AUTOSAR XML (schema 4-3-0)
package /Battery_CAN_Bus/ECUs
  ecu instance Info_Node: diagnostic-address=76773662, sleep-mode-supported=true, wake-up-over-bus-supported=true
    can communication controller Info_Node_Batt_CANController
    can communication controller Info_Node_Veh_CANController
    can communication controller Info_Node_Debug_CANController
    can communication connector Info_Node_Batt_CANConnector: comm-controller=Info_Node_Batt_CANController
    can communication connector Info_Node_Veh_CANConnector: comm-controller=Info_Node_Veh_CANController
    can communication connector Info_Node_Debug_CANConnector: comm-controller=Info_Node_Debug_CANController
  ecu instance VIC: diagnostic-address=1270719688, sleep-mode-supported=true, wake-up-over-bus-supported=true
    4 x can communication controller:
      VIC_Veh_CANController
      VIC_Batt_CANController
      VIC_Veh_J1939_CANController  # Virtual controller to handle the switch between CAN2B and J1939 in the CAN0 hw controller
      VIC_Debug_CANController
    can communication connector VIC_Veh_CANConnector: comm-controller=VIC_Veh_CANController
    can communication connector VIC_Batt_CANConnector: comm-controller=VIC_Batt_CANController
    can communication connector VIC_Veh_J1939Connector: comm-controller=VIC_Veh_J1939_CANController, pnc-wakeup-can-id-extended=true
    can communication connector VIC_Debug_CANConnector: comm-controller=VIC_Debug_CANController
package /E2E_Datatransformation
  data transformation set DATATRANSF_SET_EB
    data transformation BaseTrans_Profile_1C: execute-despite-data-unavailability=true, transformer-chain=[ComBasedTransformer, E2E_Profile_1C]  # Base Transformer Base Profile 1C
    transformation technology E2E_Profile_1C:  # E2E Profile 1C
      buffer-properties={header-length=0, in-place=false}
      needs-original-data=false
      protocol=E2E
      end-to-end-transformation-description{counter-offset=8, crc-offset=0, data-id-mode=LOWER-12-BIT, data-id-nibble-offset=12, max-delta-counter=3, max-error-state-init=1, max-error-state-invalid=1, max-error-state-valid=1, max-no-new-or-repeated-data=3, min-ok-state-init=1, min-ok-state-invalid=1, min-ok-state-valid=1, offset=0, profile-behavior=R-4--2, profile-name=PROFILE_01, sync-counter-init=1, upper-header-bits-to-shift=0, window-size=3}
      transformer-class=SAFETY
      version=1.0.0
    transformation technology ComBasedTransformer: buffer-properties={buffer-computation=compu-rational-coeffs={compu-numerator=[0, 1], compu-denominator=1}, header-length=0, in-place=false}, protocol=COMBased, transformer-class=SERIALIZER, version=1
package /Vehicle_CAN_Bus/Clusters
  can cluster Vehicle_CAN_Bus: baudrate=500000
    can physical channel Vehicle_CANChannel
      comm-connectors:
        Thermal_Management_System_ECU_CANConnector
        Vehicle_Control_Unit_CANConnector
        VIC_Veh_CANConnector
        Info_Node_Veh_CANConnector
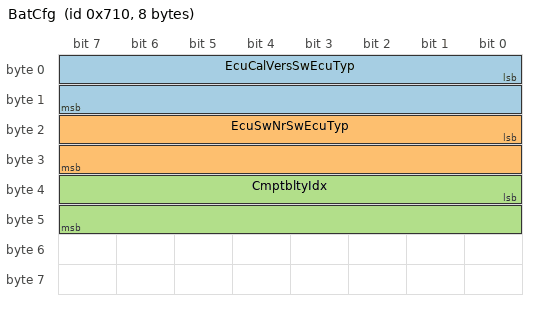
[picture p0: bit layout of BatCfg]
      frame BatCfg: id 0x710, from VIC, to Vehicle_Control_Unit, frame-length=8, can-addressing-mode=EXTENDED, can-frame-rx-behavior=CAN-20, can-frame-tx-behavior=CAN-20  # Configuration of the ECU
        pdu BatCfg: length=8, transmission-mode-true-timing=cyclic-timing=time-period=5, unused-bit-pattern=255
          signal EcuCalVersSwEcuTyp: start 0, 16 bit, little-endian, data-type-policy=OVERRIDE, base-type=EcuCalVersSwEcuTyp_Coding, compu {0=Info not available (default), 1=BMS, 2=VIC}, range phys 0..65535, to Vehicle_Control_Unit  # Calibration data ECU type
          signal EcuSwNrSwEcuTyp: start 16, 16 bit, little-endian, data-type-policy=OVERRIDE, base-type=EcuSwNrSwEcuTyp_Coding, compu {0=Info not available (default), 1=BMS, 2=VIC}, range phys 0..65535, to Vehicle_Control_Unit  # Software ECU type
          signal CmptbltyIdx: start 32, 16 bit, little-endian, data-type-policy=OVERRIDE, base-type=CmptbltyIdx_Coding, compu {identical}, range phys 0..65535, to Vehicle_Control_Unit  # Compatibility index of the CAN communication between BMS and VIC
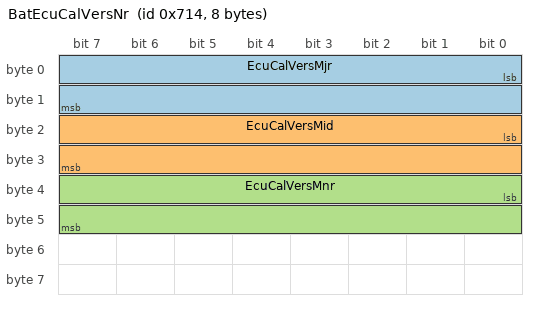
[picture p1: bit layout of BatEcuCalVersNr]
      frame BatEcuCalVersNr: id 0x714, from VIC, to Vehicle_Control_Unit, frame-length=8, can-addressing-mode=EXTENDED, can-frame-rx-behavior=CAN-20, can-frame-tx-behavior=CAN-20  # ECU calibration release numbers (unique identification in combination with BatEcuSwNr)
        pdu BatEcuCalVersNr: length=8, transmission-mode-condition{data-filter=data-filter-type=ALWAYS, i-signal-in-i-pdu=BatEcuCalVersNr_EcuCalVersMnr}, transmission-mode-true-timing=cyclic-timing=time-period=5, unused-bit-pattern=255
          signal EcuCalVersMjr: start 0, 16 bit, little-endian, data-type-policy=OVERRIDE, base-type=EcuCalVersMjr_Coding, compu {identical}, range phys 0..65535, to Vehicle_Control_Unit  # Calibration data major release number
          signal EcuCalVersMid: start 16, 16 bit, little-endian, data-type-policy=OVERRIDE, base-type=EcuCalVersMid_Coding, compu {identical}, range phys 0..65535, to Vehicle_Control_Unit  # Calibration data feature release number
          signal EcuCalVersMnr: start 32, 16 bit, little-endian, data-type-policy=OVERRIDE, base-type=EcuCalVersMnr_Coding, compu {identical}, range phys 0..65535, to Vehicle_Control_Unit  # Calibration data bugfix release number
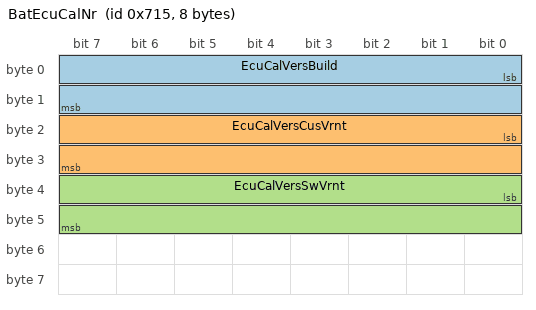
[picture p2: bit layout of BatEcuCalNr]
      frame BatEcuCalNr: id 0x715, from VIC, to Vehicle_Control_Unit, frame-length=8, can-addressing-mode=EXTENDED, can-frame-rx-behavior=CAN-20, can-frame-tx-behavior=CAN-20  # ECU calibration build and variant numbers (unique identification in combination with BatEcuCalVersNr)
        pdu BatEcuCalNr: length=8, transmission-mode-condition{data-filter=data-filter-type=ALWAYS, i-signal-in-i-pdu=BatEcuCalNr_EcuCalVersSwVrnt}, transmission-mode-true-timing=cyclic-timing=time-period=5, unused-bit-pattern=255
          signal EcuCalVersBuild: start 0, 16 bit, little-endian, data-type-policy=OVERRIDE, base-type=EcuCalVersBuild_Coding, compu {identical}, range phys 0..65535, to Vehicle_Control_Unit  # Calibration data build version number
          signal EcuCalVersCusVrnt: start 16, 16 bit, little-endian, data-type-policy=OVERRIDE, base-type=EcuCalVersCusVrnt_Coding, compu {identical}, range phys 0..65535, to Vehicle_Control_Unit  # Calibration data customer variant
          signal EcuCalVersSwVrnt: start 32, 16 bit, little-endian, data-type-policy=OVERRIDE, base-type=EcuCalVersSwVrnt_Coding, compu {identical}, range phys 0..65535, to Vehicle_Control_Unit  # Calibration data software variant
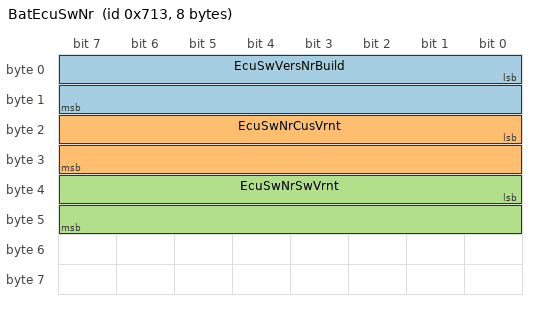
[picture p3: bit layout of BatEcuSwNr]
      frame BatEcuSwNr: id 0x713, from VIC, to Vehicle_Control_Unit, frame-length=8, can-addressing-mode=EXTENDED, can-frame-rx-behavior=CAN-20, can-frame-tx-behavior=CAN-20  # ECU software build and variant numbers (unique identification in combination with BatEcuSwVersNr)
        pdu BatEcuSwNr: length=8, transmission-mode-condition{data-filter=data-filter-type=ALWAYS, i-signal-in-i-pdu=BatEcuSwNr_EcuSwNrSwVrnt}, transmission-mode-true-timing=cyclic-timing=time-period=5, unused-bit-pattern=255
          signal EcuSwVersNrBuild: start 0, 16 bit, little-endian, data-type-policy=OVERRIDE, base-type=EcuSwVersNrBuild_Coding, compu {identical}, range phys 0..65535, to Vehicle_Control_Unit  # Software build version number
          signal EcuSwNrCusVrnt: start 16, 16 bit, little-endian, data-type-policy=OVERRIDE, base-type=EcuSwNrCusVrnt_Coding, compu {identical}, range phys 0..65535, to Vehicle_Control_Unit  # Software customer variant
          signal EcuSwNrSwVrnt: start 32, 16 bit, little-endian, data-type-policy=OVERRIDE, base-type=EcuSwNrSwVrnt_Coding, compu {identical}, range phys 0..65535, to Vehicle_Control_Unit  # Software variant
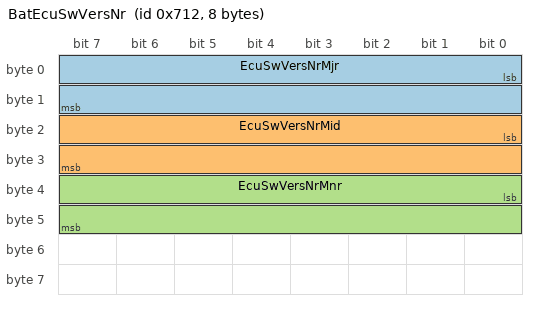
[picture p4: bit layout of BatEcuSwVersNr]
      frame BatEcuSwVersNr: id 0x712, from VIC, to Vehicle_Control_Unit, frame-length=8, can-addressing-mode=EXTENDED, can-frame-rx-behavior=CAN-20, can-frame-tx-behavior=CAN-20  # ECU software release numbers (unique identification in combination with BatEcuSwNr)
        pdu BatEcuSwVersNr: length=8, transmission-mode-condition{data-filter=data-filter-type=ALWAYS, i-signal-in-i-pdu=BatEcuSwVersNr_EcuSwVersNrMnr}, transmission-mode-true-timing=cyclic-timing=time-period=5, unused-bit-pattern=255
          signal EcuSwVersNrMjr: start 0, 16 bit, little-endian, data-type-policy=OVERRIDE, base-type=EcuSwVersNrMjr_Coding, compu {identical}, range phys 0..65535, to Vehicle_Control_Unit  # Software major release number
          signal EcuSwVersNrMid: start 16, 16 bit, little-endian, data-type-policy=OVERRIDE, base-type=EcuSwVersNrMid_Coding, compu {identical}, range phys 0..65535, to Vehicle_Control_Unit  # Software feature release number
          signal EcuSwVersNrMnr: start 32, 16 bit, little-endian, data-type-policy=OVERRIDE, base-type=EcuSwVersNrMnr_Coding, compu {identical}, range phys 0..65535, to Vehicle_Control_Unit  # Software bugfix release number
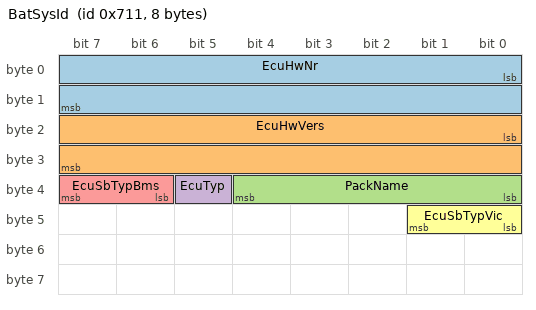
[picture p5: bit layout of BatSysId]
      frame BatSysId: id 0x711, from VIC, to Vehicle_Control_Unit, frame-length=8, can-addressing-mode=EXTENDED, can-frame-rx-behavior=CAN-20, can-frame-tx-behavior=CAN-20  # ECU hardware identification
        pdu BatSysId: length=8, transmission-mode-condition{data-filter=data-filter-type=ALWAYS, i-signal-in-i-pdu=BatSysId_EcuHwVers}, transmission-mode-true-timing=cyclic-timing=time-period=5, unused-bit-pattern=255
          signal EcuHwNr: start 0, 16 bit, little-endian, data-type-policy=OVERRIDE, base-type=EcuHwNr_Coding, compu {identical}, range phys 0..65535, to Vehicle_Control_Unit  # ECU hardware number
          signal EcuHwVers: start 16, 16 bit, little-endian, data-type-policy=OVERRIDE, base-type=EcuHwVers_Coding, compu {identical}, range phys 0..65535, to Vehicle_Control_Unit  # ECU hardware version
          signal PackName: start 32, 5 bit, little-endian, data-type-policy=OVERRIDE, base-type=PackName_Coding, compu {0=Pack1_1 or Standalone, 1..6=Pack1_2..Pack1_7, 7..12=Pack2_1..Pack2_6, 30=VIC, 31=Info not available}, range phys 0..31, to Vehicle_Control_Unit  # Name of the battery component
          signal EcuTyp: start 37, 1 bit, little-endian, data-type-policy=OVERRIDE, base-type=EcuTyp_Coding, compu {0=BMS, 1=VIC}, range phys 0..1, to Vehicle_Control_Unit  # Type of ECU
          signal EcuSbTypBms: start 38, 2 bit, little-endian, data-type-policy=OVERRIDE, base-type=EcuSbTypBms_Coding, compu {0=Standalone BMS, 1=Slave BMS in Multipack System, 2=Reserved, 3=Info not available}, range phys 0..3, to Vehicle_Control_Unit  # ECU sub-type for BMS
          signal EcuSbTypVic: start 40, 2 bit, little-endian, data-type-policy=OVERRIDE, base-type=EcuSbTypVic_Coding, compu {0=1sXp Multipack configuration, 1=2sXp Multipack configuration, 2=Reserved, 3=Info not available}, range phys 0..3, to Vehicle_Control_Unit  # ECU sub-type for VIC
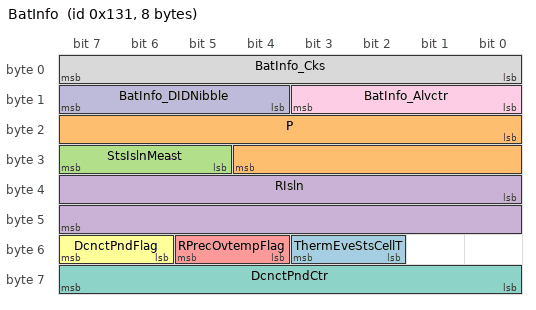
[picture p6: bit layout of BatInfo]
      frame BatInfo: id 0x131, from VIC, to Vehicle_Control_Unit, frame-length=8, can-addressing-mode=EXTENDED, can-frame-rx-behavior=CAN-20, can-frame-tx-behavior=CAN-20  # Battery operating information
        pdu BatInfo: length=8, transmission-mode-condition{data-filter=data-filter-type=ALWAYS, i-signal-in-i-pdu=BatInfo_ThermEveStsCellT}, transmission-mode-true-timing=cyclic-timing=time-period=0.1, unused-bit-pattern=255
          signal ThermEveStsCellT: start 50, 2 bit, little-endian, data-type-policy=OVERRIDE, base-type=ThermEveStsCellT_Coding, compu {3=Info not available (default), 2=Temp. crit. limit exceeded, 1=Temp. warn. limit exceeded, 0=Temperature ok}, range phys 0..3  # Warning status of cell temperature
          signal P: start 16, 13 bit, little-endian, data-type-policy=OVERRIDE, base-type=P_Coding, compu {phys=raw*0.125; unit kW}, range phys -512..511.875, unit=kW  # Electrical power flow (positive value: charge; negative value: discharge)
          signal StsIslnMeast: start 29, 3 bit, little-endian, data-type-policy=OVERRIDE, base-type=StsIslnMeast_Coding, compu {7=Info not available (default), 2=Inhibited, 1=Disabled, 0=Enabled}, range phys 0..7  # Status of the isolation measurement
          signal RIsln: start 32, 16 bit, little-endian, data-type-policy=OVERRIDE, base-type=RIsln_Coding, compu {phys=raw*8; unit kOhm}, range phys 0..524280, unit=kOhm  # Isolation resistance value
          signal RPrecOvtempFlag: start 52, 2 bit, little-endian, data-type-policy=OVERRIDE, base-type=RPrecOvtempFlag_Coding, compu {3=Info not available (default), 1=Precharge impossible, 0=Precharge possible}, range phys 0..3  # Precharge impossible due to overtemperature of the precharge resistor
          signal DcnctPndFlag: start 54, 2 bit, little-endian, data-type-policy=OVERRIDE, base-type=DcnctPndFlag_Coding, compu {3=Info not available (default), 1=Disconnection is imminent, 0=No disconnection anticipated}, range phys 0..3  # Disconnection of the battery is imminent
          signal DcnctPndCtr: start 56, 8 bit, little-endian, data-type-policy=OVERRIDE, base-type=DcnctPndCtr_Coding, range phys 0..255, compu {phys=raw*10; unit ms}, unit=ms  # Counter until the battery will be disconnected if DcnctPndFlag is set
          signal BatInfo_Cks: start 0, 8 bit, little-endian, data-type-policy=OVERRIDE, base-type=Cks_Coding, compu {phys=raw}, range phys 0..255  # CRC-8-SAE J1850 according to E2E profile 1C
          signal BatInfo_Alvctr: start 8, 4 bit, little-endian, data-type-policy=OVERRIDE, base-type=Alvctr_Coding, compu {phys=raw}, range phys 0..255  # Alive counter signal incremented every transmission (0 to 14)
          signal BatInfo_DIDNibble: start 12, 4 bit, little-endian, data-type-policy=OVERRIDE, base-type=DIDNibble_Coding, compu {phys=raw}, range phys 0..255  # Low nibble of the high byte of data ID according to E2E profile 1C
          mapping BatInfo_ISignalGroup: i-signal-group=BatInfo, packing-byte-order=little-endian, transfer-property=TRIGGERED
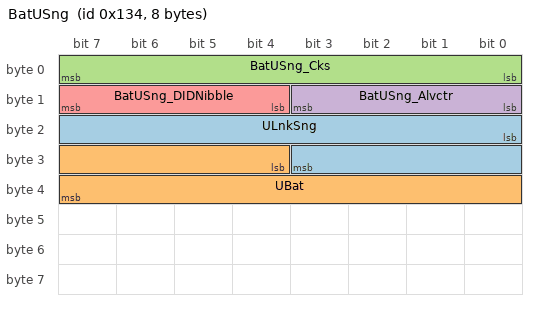
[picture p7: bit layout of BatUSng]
      frame BatUSng: id 0x134, from VIC, to Vehicle_Control_Unit, frame-length=8, can-addressing-mode=EXTENDED, can-frame-rx-behavior=CAN-20, can-frame-tx-behavior=CAN-20  # Battery voltage measurements of single pack system
        pdu BatUSng: length=8, transmission-mode-condition{data-filter=data-filter-type=ALWAYS, i-signal-in-i-pdu=BatUSng_ULnkSng}, transmission-mode-true-timing=cyclic-timing=time-period=0.1, unused-bit-pattern=255
          signal ULnkSng: start 16, 12 bit, little-endian, data-type-policy=OVERRIDE, base-type=ULnkSng_Coding, compu {phys=raw*0.5; unit V}, range phys -1024..1023.5, unit=V  # Link voltage
          signal UBat: start 28, 12 bit, little-endian, data-type-policy=OVERRIDE, base-type=UBat_Coding, compu {phys=raw*0.25; unit V}, range phys 0..1023.75, unit=V  # Battery voltage (independent of contactor status)
          signal BatUSng_Cks: start 0, 8 bit, little-endian, data-type-policy=OVERRIDE, base-type=Cks_Coding, compu {phys=raw}, range phys 0..255  # CRC-8-SAE J1850 according to E2E profile 1C
          signal BatUSng_Alvctr: start 8, 4 bit, little-endian, data-type-policy=OVERRIDE, base-type=Alvctr_Coding, compu {phys=raw}, range phys 0..255  # Alive counter signal incremented every transmission (0 to 14)
          signal BatUSng_DIDNibble: start 12, 4 bit, little-endian, data-type-policy=OVERRIDE, base-type=DIDNibble_Coding, compu {phys=raw}, range phys 0..255  # Low nibble of the high byte of data ID according to E2E profile 1C
          mapping BatUSng_ISignalGroup: i-signal-group=BatUSng, packing-byte-order=little-endian, transfer-property=TRIGGERED
      frame BatUCell: id 0x704, from VIC, to Vehicle_Control_Unit, frame-length=8, can-addressing-mode=EXTENDED, can-frame-rx-behavior=CAN-20, can-frame-tx-behavior=CAN-20  # Battery cell voltages
        pdu BatUCell: length=8, transmission-mode-condition{data-filter=data-filter-type=ALWAYS, i-signal-in-i-pdu=BatUCell_UCellMin}, transmission-mode-true-timing=cyclic-timing=time-period=0.1, unused-bit-pattern=255
          signal UCellMin: start 12, 12 bit, little-endian, data-type-policy=OVERRIDE, base-type=UCellMin_Coding, compu {phys=raw*0.002; unit V}, range phys 0..8.19, unit=V, to Vehicle_Control_Unit  # Minimal cell voltage
          signal UCellMax: start 0, 12 bit, little-endian, data-type-policy=OVERRIDE, base-type=UCellMax_Coding, compu {phys=raw*0.002; unit V}, range phys 0..8.19, unit=V, to Vehicle_Control_Unit  # Maximal cell voltage
      frame BatT: id 0x703, from VIC, to Vehicle_Control_Unit, frame-length=8, can-addressing-mode=EXTENDED, can-frame-rx-behavior=CAN-20, can-frame-tx-behavior=CAN-20  # Battery temperatures
        pdu BatT: length=8, transmission-mode-condition{data-filter=data-filter-type=ALWAYS, i-signal-in-i-pdu=BatT_TCellMin}, transmission-mode-true-timing=cyclic-timing=time-period=1, unused-bit-pattern=255
          signal TCellMin: start 11, 11 bit, little-endian, data-type-policy=OVERRIDE, base-type=TCellMin_Coding, compu {phys=raw*0.25; unit °C}, range phys -256..255.75, unit=°C, to Vehicle_Control_Unit  # Minimal cell temperature
          signal TCellMax: start 0, 11 bit, little-endian, data-type-policy=OVERRIDE, base-type=TCellMax_Coding, compu {phys=raw*0.25; unit °C}, range phys -256..255.75, unit=°C, to Vehicle_Control_Unit  # Maximal cell temperature
      frame ThermSysInfo: id 0x401, from Thermal_Management_System_ECU, to VIC, frame-length=8, can-addressing-mode=EXTENDED, can-frame-rx-behavior=CAN-20, can-frame-tx-behavior=CAN-20  # Information about the thermal management system
        pdu ThermSysInfo: length=8, transmission-mode-condition{data-filter=data-filter-type=ALWAYS, i-signal-in-i-pdu=ThermSysInfo_CoolgHeatgCfmd}, transmission-mode-true-timing=cyclic-timing=time-period=1, unused-bit-pattern=255
          signal CoolgHeatgCfmd: start 0, 10 bit, little-endian, data-type-policy=OVERRIDE, base-type=CoolgHeatgCfmd_Coding, compu {0=Off, 1=Reserved, 2=Reserved, 3=Reserved, 4=On; unit CoolgHeatgCfmd_Unit}, range phys 0..4, unit=CoolgHeatgCfmd_Unit, to VIC  # Power status of the external thermal management system
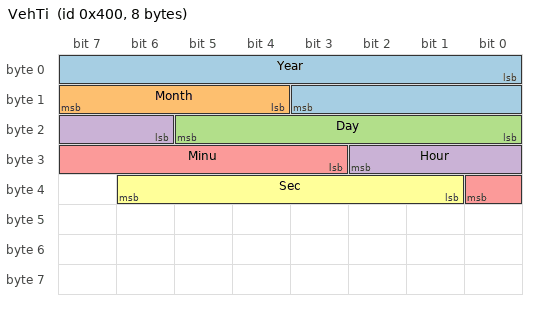
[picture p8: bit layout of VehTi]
      frame VehTi: id 0x400, from Vehicle_Control_Unit, to VIC, frame-length=8, can-addressing-mode=EXTENDED, can-frame-rx-behavior=CAN-20, can-frame-tx-behavior=CAN-20  # Vehicle time
        pdu VehTi: length=8, transmission-mode-condition{data-filter=data-filter-type=ALWAYS, i-signal-in-i-pdu=VehTi_Year}, transmission-mode-true-timing=cyclic-timing=time-period=1, unused-bit-pattern=255
          signal Year: start 0, 12 bit, little-endian, data-type-policy=OVERRIDE, base-type=Year_Coding, compu {identical; unit years}, range phys 0..4095, unit=years, to VIC  # Year in time
          signal Month: start 12, 4 bit, little-endian, data-type-policy=OVERRIDE, base-type=Month_Coding, compu {identical; unit months}, range phys 1..12, unit=months, to VIC  # Month (within the year)
          signal Day: start 16, 6 bit, little-endian, data-type-policy=OVERRIDE, base-type=Day_Coding, compu {identical; unit days}, range phys 0..63, unit=days, to VIC  # Day (within the month)
          signal Hour: start 22, 5 bit, little-endian, data-type-policy=OVERRIDE, base-type=Hour_Coding, compu {identical; unit h}, range phys 0..24, unit=h, to VIC  # Hour (within the day)
          signal Minu: start 27, 6 bit, little-endian, data-type-policy=OVERRIDE, base-type=Minu_Coding, compu {identical; unit min}, range phys 0..59, unit=min, to VIC  # Minute (within the hour)
          signal Sec: start 33, 6 bit, little-endian, data-type-policy=OVERRIDE, base-type=Sec_Coding, compu {identical; unit s}, range phys 0..60, unit=s, to VIC  # Second (within the minute)
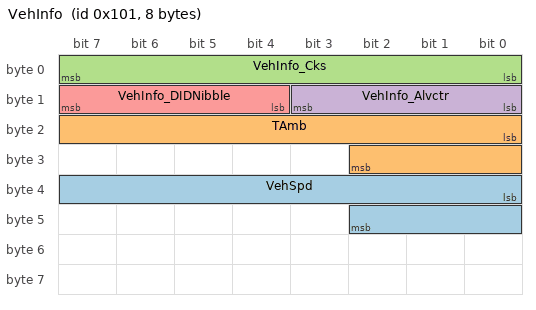
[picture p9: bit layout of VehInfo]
      frame VehInfo: id 0x101, from Vehicle_Control_Unit, to VIC, frame-length=8, can-addressing-mode=EXTENDED, can-frame-rx-behavior=CAN-20, can-frame-tx-behavior=CAN-20  # Vehicle status information
        pdu VehInfo: length=8, transmission-mode-condition{data-filter=data-filter-type=ALWAYS, i-signal-in-i-pdu=VehInfo_VehSpd}, transmission-mode-true-timing=cyclic-timing=time-period=0.1, unused-bit-pattern=255
          signal VehSpd: start 32, 11 bit, little-endian, data-type-policy=OVERRIDE, base-type=VehSpd_Coding, compu {phys=raw*0.5; unit km/h}, range phys -512..511.5, unit=km/h  # Vehicle speed
          signal TAmb: start 16, 11 bit, little-endian, data-type-policy=OVERRIDE, base-type=TAmb_Coding, compu {phys=raw*0.25; unit °C}, range phys -256..255.75, unit=°C  # Ambient temperature
          signal VehInfo_Cks: start 0, 8 bit, little-endian, data-type-policy=OVERRIDE, base-type=Cks_Coding, compu {phys=raw}, range phys 0..255  # CRC-8-SAE J1850 according to E2E profile 1C
          signal VehInfo_Alvctr: start 8, 4 bit, little-endian, data-type-policy=OVERRIDE, base-type=Alvctr_Coding, compu {phys=raw}, range phys 0..255  # Alive counter signal incremented every transmission (0 to 14)
          signal VehInfo_DIDNibble: start 12, 4 bit, little-endian, data-type-policy=OVERRIDE, base-type=DIDNibble_Coding, compu {phys=raw}, range phys 0..255  # Low nibble of the high byte of data ID according to E2E profile 1C
          mapping VehInfo_ISignalGroup: i-signal-group=VehInfo, packing-byte-order=little-endian, transfer-property=TRIGGERED
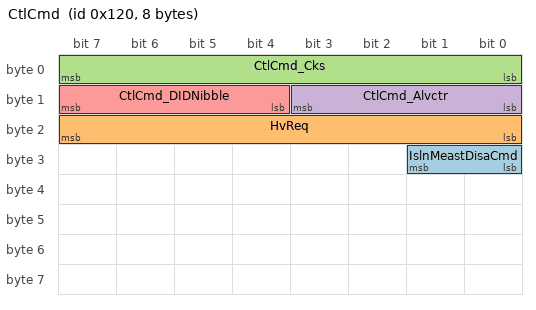
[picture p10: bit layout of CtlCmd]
      frame CtlCmd: id 0x120, from Vehicle_Control_Unit, to VIC, frame-length=8, can-addressing-mode=EXTENDED, can-frame-rx-behavior=CAN-20, can-frame-tx-behavior=CAN-20  # Commands to control the battery
        pdu CtlCmd: length=8, transmission-mode-true-timing=cyclic-timing=time-period=0.1, unused-bit-pattern=255
          signal IslnMeastDisaCmd: start 24, 2 bit, little-endian, data-type-policy=OVERRIDE, base-type=IslnMeastDisaCmd_Coding, compu {3=Info not available (default), 2=Reserved, 1=Disable, 0=Enable}, range phys 0..3  # Command to disable the isolation measurement
          signal HvReq: start 16, 8 bit, little-endian, data-type-policy=OVERRIDE, base-type=HvReq_Coding, range phys 0..255, compu {255=Info not available (default), 50=Disconnect DC char. (VIB only), 49=Connect for DC char. (VIB only), 48=Prepare for DC char. (VIB only), 32=Connect for AC charging, 16=Connect for driving, 1=Emergency disconnect, 0=Disconnect, 51=Connect for DC char. GBT (VIB only)}  # High voltage request
          signal CtlCmd_Cks: start 0, 8 bit, little-endian, data-type-policy=OVERRIDE, base-type=Cks_Coding, compu {phys=raw}, range phys 0..255  # CRC-8-SAE J1850 according to E2E profile 1C
          signal CtlCmd_Alvctr: start 8, 4 bit, little-endian, data-type-policy=OVERRIDE, base-type=Alvctr_Coding, compu {phys=raw}, range phys 0..255  # Alive counter signal incremented every transmission (0 to 14)
          signal CtlCmd_DIDNibble: start 12, 4 bit, little-endian, data-type-policy=OVERRIDE, base-type=DIDNibble_Coding, compu {phys=raw}, range phys 0..255  # Low nibble of the high byte of data ID according to E2E profile 1C
          mapping CtlCmd_ISignalGroup: i-signal-group=CtlCmd, packing-byte-order=little-endian, transfer-property=TRIGGERED
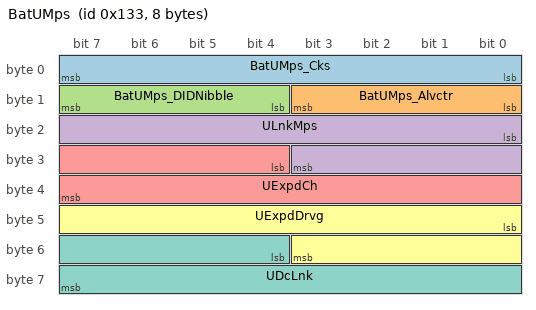
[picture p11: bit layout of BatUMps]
      frame BatUMps: id 0x133, from VIC, to Vehicle_Control_Unit, frame-length=8, can-addressing-mode=EXTENDED, can-frame-rx-behavior=CAN-20, can-frame-tx-behavior=CAN-20  # Battery voltage measurements of multipack system
        pdu BatUMps: length=8, transmission-mode-true-timing=cyclic-timing=time-period=0.1, unused-bit-pattern=255
          signal BatUMps_Cks: start 0, 8 bit, little-endian, data-type-policy=OVERRIDE, base-type=Cks_Coding, compu {phys=raw}, range phys 0..255  # CRC-8-SAE J1850 according to E2E profile 1C
          signal BatUMps_Alvctr: start 8, 4 bit, little-endian, data-type-policy=OVERRIDE, base-type=Alvctr_Coding, compu {phys=raw}, range phys 0..255  # Alive counter signal incremented every transmission (0 to 14)
          signal BatUMps_DIDNibble: start 12, 4 bit, little-endian, data-type-policy=OVERRIDE, base-type=DIDNibble_Coding, compu {phys=raw}, range phys 0..255  # Low nibble of the high byte of data ID according to E2E profile 1C
          signal ULnkMps: start 16, 12 bit, little-endian, data-type-policy=OVERRIDE, base-type=ULnkMps_Coding, compu {phys=raw*0.5; unit V}, range phys -1024..1023.5, unit=V  # Link voltage
          signal UExpdCh: start 28, 12 bit, little-endian, data-type-policy=OVERRIDE, base-type=UExpdCh_Coding, compu {phys=raw*0.25; unit V}, range phys 0..1023.75, unit=V  # Expected link voltage when connected for charging
          signal UExpdDrvg: start 40, 12 bit, little-endian, data-type-policy=OVERRIDE, base-type=UExpdDrvg_Coding, compu {phys=raw*0.25; unit V}, range phys 0..1023.75, unit=V  # Expected link voltage when connected for driving
          signal UDcLnk: start 52, 12 bit, little-endian, data-type-policy=OVERRIDE, base-type=UDcLnk_Coding, compu {phys=raw*0.25; unit V}, range phys 0..1023.75, unit=V  # Link voltage at DC charging socket
          mapping BatUMps_ISignalGroup: i-signal-group=BatUMps, packing-byte-order=little-endian, transfer-property=TRIGGERED
      frame BatThermReq2: id 0x721, from VIC, to Vehicle_Control_Unit Thermal_Management_System_ECU, frame-length=8, can-addressing-mode=EXTENDED, can-frame-rx-behavior=CAN-20, can-frame-tx-behavior=CAN-20  # Coolant/heating request for an external thermal management system with on/off control
        pdu BatThermReq2: length=8, transmission-mode-condition{data-filter=data-filter-type=ALWAYS, i-signal-in-i-pdu=BatThermReq2_ThermSysStrtReq2}, transmission-mode-true-timing=cyclic-timing=time-period=1, unused-bit-pattern=255
          signal ThermSysStrtReq2: start 0, 2 bit, little-endian, data-type-policy=OVERRIDE, base-type=ThermSysStrtReq2_Coding, compu {3=Info not available (default), 2=Reserved, 1=Active, 0=Not active}, range phys 0..3, to Vehicle_Control_Unit  # Wakeup request for an external thermal management system with on/off control
          signal CoolgHeatgReq: start 7, 2 bit, little-endian, data-type-policy=OVERRIDE, base-type=CoolgHeatgReq_Coding, compu {3=Info not available (default), 2=Reserved, 1=Activate, 0=Deactivate}, range phys 0..3, to Thermal_Management_System_ECU  # Request for coolant/heating flow for an external thermal management system with on/off control
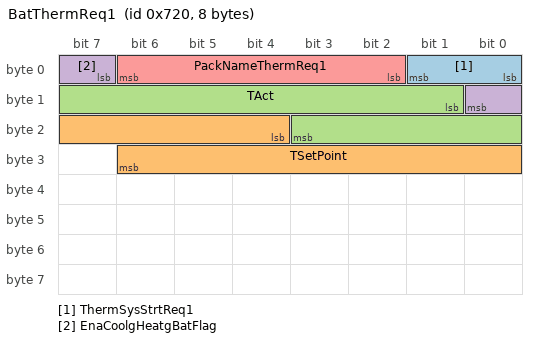
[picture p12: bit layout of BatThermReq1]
      frame BatThermReq1: id 0x720, from VIC, to Vehicle_Control_Unit Thermal_Management_System_ECU, frame-length=8, can-addressing-mode=EXTENDED, can-frame-rx-behavior=CAN-20, can-frame-tx-behavior=CAN-20  # Coolant/heating request for an external thermal management system with setpoint control
        pdu BatThermReq1: length=8, transmission-mode-condition{data-filter=data-filter-type=ALWAYS, i-signal-in-i-pdu=BatThermReq1_ThermSysStrtReq1}, transmission-mode-true-timing=cyclic-timing=time-period=0.1, unused-bit-pattern=255
          signal ThermSysStrtReq1: start 0, 2 bit, little-endian, data-type-policy=OVERRIDE, base-type=ThermSysStrtReq1_Coding, compu {3=Info not available (default), 2=Reserved, 1=Active, 0=Not active}, range phys 0..3, to Vehicle_Control_Unit  # Wakeup request for an external thermal management system with setpoint control
          signal TSetPoint: start 20, 11 bit, little-endian, data-type-policy=OVERRIDE, base-type=TSetPoint_Coding, compu {phys=raw*0.25; unit °C}, range phys -256..255.75, unit=°C, to Thermal_Management_System_ECU  # Setpoint temperature for an external thermal management system for pack mentioned in PackNameThermReq1 (multiplexed signal)
          signal TAct: start 9, 11 bit, little-endian, data-type-policy=OVERRIDE, base-type=TAct_Coding, compu {phys=raw*0.25; unit °C}, range phys -256..255.75, unit=°C, to Thermal_Management_System_ECU  # Cell temperature of pack mentioned in PackNameThermReq1 with the highest absolute deviation from the setpoint temperature (multiplexed signal)
          signal EnaCoolgHeatgBatFlag: start 7, 2 bit, little-endian, data-type-policy=OVERRIDE, base-type=EnaCoolgHeatgBatFlag_Coding, compu {3=Info not available (default), 2=Reserved, 1=Activate, 0=Deactivate}, range phys 0..3, to Thermal_Management_System_ECU  # Request for coolant/heating flow for an external thermal management system with setpoint control from pack mentioned in PackNameThermReq1 (multiplexed signal)
          signal PackNameThermReq1: start 2, 5 bit, little-endian, data-type-policy=OVERRIDE, base-type=PackNameThermReq1_Coding, compu {31=Info not available, 30=VIC, 12=Pack2_6, 11=Pack2_5, 10=Pack2_4, 9=Pack2_3, 8=Pack2_2, 7=Pack2_1, 6=Pack1_7, 5=Pack1_6, 4=Pack1_5, 3=Pack1_4, 2=Pack1_3, 1=Pack1_2, 0=Pack1_1 or Standalone}, range phys 0..15, to Thermal_Management_System_ECU  # Battery pack the multiplexed signals in this message refer to (multiplexor signal)
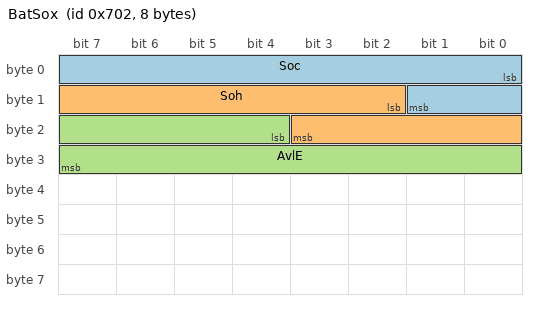
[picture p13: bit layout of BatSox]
      frame BatSox: id 0x702, from VIC, to Vehicle_Control_Unit, frame-length=8, can-addressing-mode=EXTENDED, can-frame-rx-behavior=CAN-20, can-frame-tx-behavior=CAN-20  # SoC, SoH and energy
        pdu BatSox: length=8, transmission-mode-condition{data-filter=data-filter-type=ALWAYS, i-signal-in-i-pdu=BatSox_Soh}, transmission-mode-true-timing=cyclic-timing=time-period=1, unused-bit-pattern=255
          signal Soc: start 0, 10 bit, little-endian, data-type-policy=OVERRIDE, base-type=Soc_Coding, compu {phys=raw*0.125; unit %}, range phys 0..100, unit=%, to Vehicle_Control_Unit  # State of charge
          signal Soh: start 10, 10 bit, little-endian, data-type-policy=OVERRIDE, base-type=Soh_Coding, compu {phys=raw*0.125; unit %}, range phys 0..100, unit=%, to Vehicle_Control_Unit  # State of health
          signal AvlE: start 20, 12 bit, little-endian, data-type-policy=OVERRIDE, base-type=AvlE_Coding, compu {phys=raw*0.25; unit kWh}, range phys 0..1023.75, unit=kWh, to Vehicle_Control_Unit  # Available energy
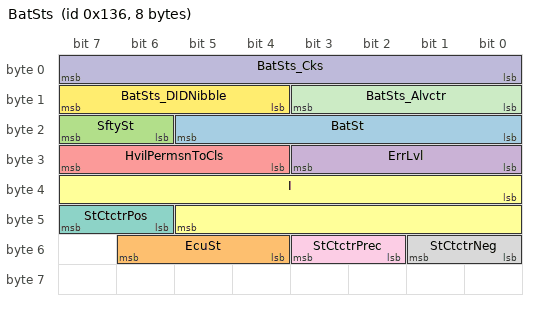
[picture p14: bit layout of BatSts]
      frame BatSts: id 0x136, from VIC, to Vehicle_Control_Unit, frame-length=8, can-addressing-mode=EXTENDED, can-frame-rx-behavior=CAN-20, can-frame-tx-behavior=CAN-20  # Battery status signals
        pdu BatSts: length=8, transmission-mode-true-timing=cyclic-timing=time-period=0.01, unused-bit-pattern=255
          signal BatSt: start 16, 6 bit, little-endian, data-type-policy=OVERRIDE, base-type=BatSt_Coding, compu {63=Info not available (default), 62=In service mode, 54=Connected, DC contactors opened, 53=Connected for DC charging, 48=Prepared for DC charging, 37=Connected for AC charging, 23=Disconnecting, 16=Connecting, 21=Connected, 3=Disconnected, awaiting HV req., 2=Disconnected, not ready, 1=Emergeny disconnecting, 0=Initialising, 55=Connected for DC charging GBT}, range phys 0..63  # Status of the battery system
          signal EcuSt: start 52, 3 bit, little-endian, data-type-policy=OVERRIDE, base-type=EcuSt_Coding, compu {3=Wait/Com_Latch, 2=Power Latch, 1=Run, 0=Startup, 4=Shutdown, 5=ComReq, 6=ReqIdle, 7=SysChk}, range phys 0..7  # Status of the ECU
          signal SftySt: start 22, 2 bit, little-endian, data-type-policy=OVERRIDE, init-value=3, base-type=SftySt_Coding, compu {0=Safety monitoring not ok, 1=Safety monitoring ok, 2=Reserved, 3=Info not available (default)}, range phys 0..3  # Consolidated status of the safety function diagnosis (PermsnToCls) to the commanding component
          signal ErrLvl: start 24, 4 bit, little-endian, data-type-policy=OVERRIDE, base-type=ErrLvl_Coding, compu {0=System is ok, 1=Minor system failure, performance unaffected, 2=Limp Home with limited power, 3=Open contactors with speed limit, 4=Open contactors with time limit, 5=Open contactors normal, 6=Open contactors immediately, 7=Open contactors immediately and lock}, range phys 0..7  # Error level value
          signal HvilPermsnToCls: start 28, 4 bit, little-endian, data-type-policy=OVERRIDE, base-type=HvilPermsnToCls_Coding, compu {15=Info not available (default), 11=Granted but error, 10=Granted, 2=Denied permanently, 1=Denied until restart, 0=Denied due to initialization}, range phys 0..15  # Permission to activate HV by the connector (HVIL) safety function
          signal I: start 32, 14 bit, little-endian, data-type-policy=OVERRIDE, base-type=I_Coding, compu {phys=raw*0.25; unit A}, range phys -2048..2047.75, unit=A  # Current flow (positive value: charge; negative value: discharge)
          signal StCtctrPos: start 46, 2 bit, little-endian, data-type-policy=OVERRIDE, base-type=StCtctrPos_Coding, compu {0=Open, 1=Closed, 2=Unknown, 3=Information not available}, range phys 0..3  # Status of the contactors on the positive terminal
          signal StCtctrNeg: start 48, 2 bit, little-endian, data-type-policy=OVERRIDE, base-type=StCtctrNeg_Coding, compu {0=Open, 1=Closed, 2=Unknown, 3=Information not available}, range phys 0..3  # Status of the contactors on the negative terminal
          signal StCtctrPrec: start 50, 2 bit, little-endian, data-type-policy=OVERRIDE, base-type=StCtctrPrec_Coding, compu {0=Open, 1=Closed, 2=Unknown, 3=Information not available}, range phys 0..3  # Status of the contactors on the precharge circuit
          signal BatSts_Cks: start 0, 8 bit, little-endian, data-type-policy=OVERRIDE, base-type=Cks_Coding, compu {phys=raw}, range phys 0..255  # CRC-8-SAE J1850 according to E2E profile 1C
          signal BatSts_Alvctr: start 8, 4 bit, little-endian, data-type-policy=OVERRIDE, base-type=Alvctr_Coding, compu {phys=raw}, range phys 0..255  # Alive counter signal incremented every transmission (0 to 14)
          signal BatSts_DIDNibble: start 12, 4 bit, little-endian, data-type-policy=OVERRIDE, base-type=DIDNibble_Coding, compu {phys=raw}, range phys 0..255  # Low nibble of the high byte of data ID according to E2E profile 1C
          mapping BatSts_ISignalGroup: i-signal-group=BatSts, packing-byte-order=little-endian, start-position=32, transfer-property=TRIGGERED
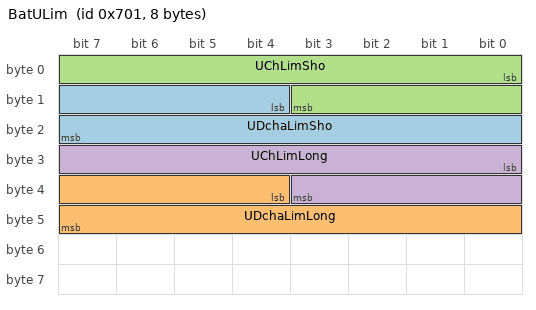
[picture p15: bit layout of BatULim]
      frame BatULim: id 0x701, from VIC, to Vehicle_Control_Unit, frame-length=8, can-addressing-mode=EXTENDED, can-frame-rx-behavior=CAN-20, can-frame-tx-behavior=CAN-20  # Battery voltage limits
        pdu BatULim: length=8, transmission-mode-condition{data-filter=data-filter-type=ALWAYS, i-signal-in-i-pdu=BatULim_UDchaLimSho}, transmission-mode-true-timing=cyclic-timing=time-period=0.1, unused-bit-pattern=255
          signal UDchaLimSho: start 12, 12 bit, little-endian, data-type-policy=OVERRIDE, base-type=UDchaLimSho_Coding, compu {phys=raw*0.25; unit V}, range phys 0..1023.75, unit=V, to Vehicle_Control_Unit  # Short term voltage limit for discharging
          signal UDchaLimLong: start 36, 12 bit, little-endian, data-type-policy=OVERRIDE, base-type=UDchaLimLong_Coding, compu {phys=raw*0.25; unit V}, range phys 0..1023.75, unit=V, to Vehicle_Control_Unit  # Long term voltage limit for discharging
          signal UChLimSho: start 0, 12 bit, little-endian, data-type-policy=OVERRIDE, base-type=UChLimSho_Coding, compu {phys=raw*0.25; unit V}, range phys 0..1023.75, unit=V, to Vehicle_Control_Unit  # Short term voltage limit for charging
          signal UChLimLong: start 24, 12 bit, little-endian, data-type-policy=OVERRIDE, base-type=UChLimLong_Coding, compu {phys=raw*0.25; unit V}, range phys 0..1023.75, unit=V, to Vehicle_Control_Unit  # Long term voltage limit for charging
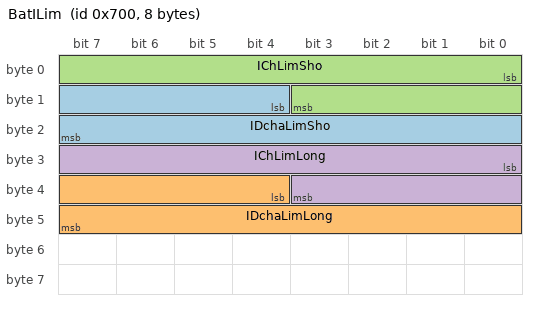
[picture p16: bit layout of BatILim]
      frame BatILim: id 0x700, from VIC, to Vehicle_Control_Unit, frame-length=8, can-addressing-mode=EXTENDED, can-frame-rx-behavior=CAN-20, can-frame-tx-behavior=CAN-20  # Battery current limits
        pdu BatILim: length=8, transmission-mode-condition{data-filter=data-filter-type=ALWAYS, i-signal-in-i-pdu=BatILim_IDchaLimSho}, transmission-mode-true-timing=cyclic-timing=time-period=0.1, unused-bit-pattern=255
          signal IDchaLimSho: start 12, 12 bit, little-endian, data-type-policy=OVERRIDE, base-type=IDchaLimSho_Coding, compu {phys=raw*0.5; unit A}, range phys 0..2047.5, unit=A, to Vehicle_Control_Unit  # Short term current limit for discharging
          signal IDchaLimLong: start 36, 12 bit, little-endian, data-type-policy=OVERRIDE, base-type=IDchaLimLong_Coding, compu {phys=raw*0.5; unit A}, range phys 0..2047.5, unit=A, to Vehicle_Control_Unit  # Long term current limit for discharging
          signal IChLimSho: start 0, 12 bit, little-endian, data-type-policy=OVERRIDE, base-type=IChLimSho_Coding, compu {phys=raw*0.5; unit A}, range phys 0..2047.5, unit=A, to Vehicle_Control_Unit  # Short term current limit for charging
          signal IChLimLong: start 24, 12 bit, little-endian, data-type-policy=OVERRIDE, base-type=IChLimLong_Coding, compu {phys=raw*0.5; unit A}, range phys 0..2047.5, unit=A, to Vehicle_Control_Unit  # Long term current limit for charging
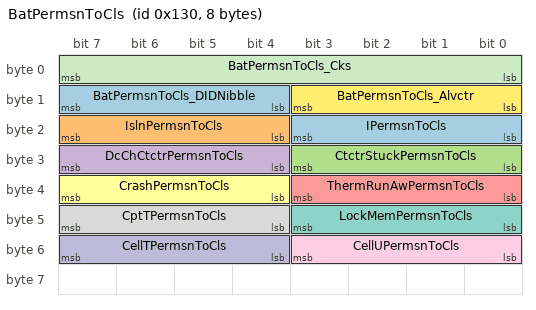
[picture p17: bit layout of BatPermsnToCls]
      frame BatPermsnToCls: id 0x130, from VIC, to Vehicle_Control_Unit, frame-length=8, can-addressing-mode=EXTENDED, can-frame-rx-behavior=CAN-20, can-frame-tx-behavior=CAN-20  # Permissions to activate HV by the safety functions
        pdu BatPermsnToCls: length=8, transmission-mode-condition{data-filter=data-filter-type=ALWAYS, i-signal-in-i-pdu=BatPermsnToCls_LockMemPermsnToCls}, transmission-mode-true-timing=cyclic-timing=time-period=0.1, unused-bit-pattern=255
          signal IPermsnToCls: start 16, 4 bit, little-endian, data-type-policy=OVERRIDE, base-type=IPermsnToCls_Coding, compu {15=Info not available (default), 11=Granted but error, 10=Granted, 2=Denied permanently, 1=Denied until restart, 0=Denied due to initialization}, range phys 0..15  # Permission to activate HV by the current safety function
          signal IslnPermsnToCls: start 20, 4 bit, little-endian, data-type-policy=OVERRIDE, base-type=IslnPermsnToCls_Coding, compu {15=Info not available (default), 11=Granted but error, 10=Granted, 2=Denied permanently, 1=Denied until restart, 0=Denied due to initialization}, range phys 0..15  # Permission to activate HV by the isolation safety function
          signal CtctrStuckPermsnToCls: start 24, 4 bit, little-endian, data-type-policy=OVERRIDE, base-type=CtctrStuckPermsnToCls_Coding, compu {15=Info not available (default), 11=Granted but error, 10=Granted, 2=Denied permanently, 1=Denied until restart, 0=Denied due to initialization}, range phys 0..15  # Permission to activate HV by the main and precharge contactor stuck safety function
          signal DcChCtctrPermsnToCls: start 28, 4 bit, little-endian, data-type-policy=OVERRIDE, base-type=DcChCtctrPermsnToCls_Coding, compu {15=Info not available (default), 11=Granted but error, 10=Granted, 2=Denied permanently, 1=Denied until restart, 0=Denied due to initialization}, range phys 0..15  # Permission to activate HV by the DC charging contactor stuck safety function
          signal ThermRunAwPermsnToCls: start 32, 4 bit, little-endian, data-type-policy=OVERRIDE, base-type=ThermRunAwPermsnToCls_Coding, compu {15=Info not available (default), 11=Granted but error, 10=Granted, 2=Denied permanently, 1=Denied until restart, 0=Denied due to initialization}, range phys 0..15  # Permission to activate HV by the thermal runaway safety function
          signal CrashPermsnToCls: start 36, 4 bit, little-endian, data-type-policy=OVERRIDE, base-type=CrashPermsnToCls_Coding, compu {15=Info not available (default), 11=Granted but error, 10=Granted, 2=Denied permanently, 1=Denied until restart, 0=Denied due to initialization}, range phys 0..15  # Permission to activate HV by the crash safety function
          signal LockMemPermsnToCls: start 40, 4 bit, little-endian, data-type-policy=OVERRIDE, base-type=LockMemPermsnToCls_Coding, compu {15=Info not available (default), 11=Granted but error, 10=Granted, 2=Denied permanently, 1=Denied until restart, 0=Denied due to initialization}, range phys 0..15  # Permission to activate HV by the lock memory safety function
          signal CptTPermsnToCls: start 44, 4 bit, little-endian, data-type-policy=OVERRIDE, base-type=CptTPermsnToCls_Coding, compu {15=Info not available (default), 11=Granted but error, 10=Granted, 2=Denied permanently, 1=Denied until restart, 0=Denied due to initialization}, range phys 0..15  # Permission to activate HV by the component temperature safety function
          signal CellUPermsnToCls: start 48, 4 bit, little-endian, data-type-policy=OVERRIDE, base-type=CellUPermsnToCls_Coding, compu {15=Info not available (default), 11=Granted but error, 10=Granted, 2=Denied permanently, 1=Denied until restart, 0=Denied due to initialization}, range phys 0..15  # Permission to activate HV by the cell voltage safety function
          signal CellTPermsnToCls: start 52, 4 bit, little-endian, data-type-policy=OVERRIDE, base-type=CellTPermsnToCls_Coding, compu {15=Info not available (default), 11=Granted but error, 10=Granted, 2=Denied permanently, 1=Denied until restart, 0=Denied due to initialization}, range phys 0..15  # Permission to activate HV by the cell temperature safety function
          signal BatPermsnToCls_Cks: start 0, 8 bit, little-endian, data-type-policy=OVERRIDE, base-type=Cks_Coding, compu {phys=raw}, range phys 0..255  # CRC-8-SAE J1850 according to E2E profile 1C
          signal BatPermsnToCls_Alvctr: start 8, 4 bit, little-endian, data-type-policy=OVERRIDE, base-type=Alvctr_Coding, compu {phys=raw}, range phys 0..255  # Alive counter signal incremented every transmission (0 to 14)
          signal BatPermsnToCls_DIDNibble: start 12, 4 bit, little-endian, data-type-policy=OVERRIDE, base-type=DIDNibble_Coding, compu {phys=raw}, range phys 0..255  # Low nibble of the high byte of data ID according to E2E profile 1C
          mapping BatPermsnToCls_ISignalGroup: i-signal-group=BatPermsnToCls, packing-byte-order=little-endian, transfer-property=TRIGGERED
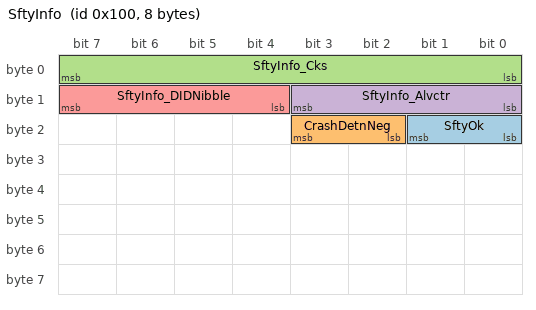
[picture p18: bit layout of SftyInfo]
      frame SftyInfo: id 0x100, from Vehicle_Control_Unit, to VIC, frame-length=8, can-addressing-mode=EXTENDED, can-frame-rx-behavior=CAN-20, can-frame-tx-behavior=CAN-20  # Safety relevant information
        pdu SftyInfo: length=8, transmission-mode-true-timing=cyclic-timing=time-period=0.01, unused-bit-pattern=255
          signal SftyOk: start 16, 2 bit, little-endian, data-type-policy=OVERRIDE, base-type=SftyOk_Coding, compu {3=Info not available (default), 2=Reserved, 1=Concession granted, 0=No concession}, range phys 0..3  # Concession for executing safety relevant actions from the commanding component to the executing component
          signal CrashDetnNeg: start 18, 2 bit, little-endian, data-type-policy=OVERRIDE, base-type=CrashDetnNeg_Coding, compu {3=Info not available (default), 2=Reserved, 1=No crash detected, 0=Crash detected}, range phys 0..3  # Crash detection indication
          signal SftyInfo_Cks: start 0, 8 bit, little-endian, data-type-policy=OVERRIDE, base-type=Cks_Coding, compu {phys=raw}, range phys 0..255  # CRC-8-SAE J1850 according to E2E profile 1C
          signal SftyInfo_Alvctr: start 8, 4 bit, little-endian, data-type-policy=OVERRIDE, base-type=Alvctr_Coding, compu {phys=raw}, range phys 0..255  # Alive counter signal incremented every transmission (0 to 14)
          signal SftyInfo_DIDNibble: start 12, 4 bit, little-endian, data-type-policy=OVERRIDE, base-type=DIDNibble_Coding, compu {phys=raw}, range phys 0..255  # Low nibble of the high byte of data ID according to E2E profile 1C
          mapping SftyInfo_ISignalGroup: i-signal-group=SftyInfo, packing-byte-order=little-endian, transfer-property=TRIGGERED
      frame UdsComRx_VIB_BMSStdAln: id 0x780, from VIC, to Info_Node, frame-length=8, can-addressing-mode=EXTENDED, can-frame-rx-behavior=CAN-20, can-frame-tx-behavior=CAN-20  # UDS response message from the battery system
        pdu UdsComRx_VIB_BMSStdAln: length=8, unused-bit-pattern=0
      frame UdsComTx_VIBToPack1_1: id 0x686, from Info_Node, to VIC, frame-length=8, can-addressing-mode=EXTENDED, can-frame-rx-behavior=CAN-20, can-frame-tx-behavior=CAN-20  # UDS request message to Pack1_1 routed via VIC
        pdu UdsComTx_VIBToPack1_1: length=8, unused-bit-pattern=0
      frame UdsComTx_VIBToPack1_2: id 0x68C, from Info_Node, to VIC, frame-length=8, can-addressing-mode=EXTENDED, can-frame-rx-behavior=CAN-20, can-frame-tx-behavior=CAN-20  # UDS request message to Pack1_2 routed via VIC
        pdu UdsComTx_VIBToPack1_2: length=8, unused-bit-pattern=0
      frame UdsComTx_VIBToPack1_3: id 0x692, from Info_Node, to VIC, frame-length=8, can-addressing-mode=EXTENDED, can-frame-rx-behavior=CAN-20, can-frame-tx-behavior=CAN-20  # UDS request message to Pack1_3 routed via VIC
        pdu UdsComTx_VIBToPack1_3: length=8, unused-bit-pattern=0
      frame UdsComTx_VIBToPack1_4: id 0x698, from Info_Node, to VIC, frame-length=8, can-addressing-mode=EXTENDED, can-frame-rx-behavior=CAN-20, can-frame-tx-behavior=CAN-20  # UDS request message to Pack1_4 routed via VIC
        pdu UdsComTx_VIBToPack1_4: length=8, unused-bit-pattern=0
      frame UdsComTx_VIBToPack1_5: id 0x69E, from Info_Node, to VIC, frame-length=8, can-addressing-mode=EXTENDED, can-frame-rx-behavior=CAN-20, can-frame-tx-behavior=CAN-20  # UDS request message to Pack1_5 routed via VIC
        pdu UdsComTx_VIBToPack1_5: length=8, unused-bit-pattern=0
      frame UdsComTx_VIBToPack2_1: id 0x6B0, from Info_Node, to VIC, frame-length=8, can-addressing-mode=EXTENDED, can-frame-rx-behavior=CAN-20, can-frame-tx-behavior=CAN-20  # UDS request message to Pack2_1 routed via VIC
        pdu UdsComTx_VIBToPack2_1: length=8, unused-bit-pattern=0
      frame UdsComTx_VIBToPack2_2: id 0x6B6, from Info_Node, to VIC, frame-length=8, can-addressing-mode=EXTENDED, can-frame-rx-behavior=CAN-20, can-frame-tx-behavior=CAN-20  # UDS request message to Pack2_2 routed via VIC
        pdu UdsComTx_VIBToPack2_2: length=8, unused-bit-pattern=0
      frame UdsComTx_VIBToPack2_3: id 0x6BC, from Info_Node, to VIC, frame-length=8, can-addressing-mode=EXTENDED, can-frame-rx-behavior=CAN-20, can-frame-tx-behavior=CAN-20  # UDS request message to Pack2_3 routed via VIC
        pdu UdsComTx_VIBToPack2_3: length=8, unused-bit-pattern=0
      frame UdsComTx_VIBToPack2_4: id 0x6C2, from Info_Node, to VIC, frame-length=8, can-addressing-mode=EXTENDED, can-frame-rx-behavior=CAN-20, can-frame-tx-behavior=CAN-20  # UDS request message to Pack2_4 routed via VIC
        pdu UdsComTx_VIBToPack2_4: length=8, unused-bit-pattern=0
      frame UdsComTx_VIBToPack2_5: id 0x6C8, from Info_Node, to VIC, frame-length=8, can-addressing-mode=EXTENDED, can-frame-rx-behavior=CAN-20, can-frame-tx-behavior=CAN-20  # UDS request message to Pack2_5 routed via VIC
        pdu UdsComTx_VIBToPack2_5: length=8, unused-bit-pattern=0
      frame UdsComRx_VIBFromPack1_1: id 0x786, from VIC, to Info_Node, frame-length=8, can-addressing-mode=EXTENDED, can-frame-rx-behavior=CAN-20, can-frame-tx-behavior=CAN-20  # UDS response message from Pack1_1 routed via VIC
        pdu UdsComRx_VIBFromPack1_1: length=8, unused-bit-pattern=0
      frame UdsComRx_VIBFromPack1_2: id 0x78C, from VIC, to Info_Node, frame-length=8, can-addressing-mode=EXTENDED, can-frame-rx-behavior=CAN-20, can-frame-tx-behavior=CAN-20  # UDS response message from Pack1_2 routed via VIC
        pdu UdsComRx_VIBFromPack1_2: length=8, unused-bit-pattern=0
      frame UdsComRx_VIBFromPack1_3: id 0x792, from VIC, to Info_Node, frame-length=8, can-addressing-mode=EXTENDED, can-frame-rx-behavior=CAN-20, can-frame-tx-behavior=CAN-20  # UDS response message from Pack1_3 routed via VIC
        pdu UdsComRx_VIBFromPack1_3: length=8, unused-bit-pattern=0
      frame UdsComRx_VIBFromPack1_4: id 0x798, from VIC, to Info_Node, frame-length=8, can-addressing-mode=EXTENDED, can-frame-rx-behavior=CAN-20, can-frame-tx-behavior=CAN-20  # UDS response message from Pack1_4 routed via VIC
        pdu UdsComRx_VIBFromPack1_4: length=8, unused-bit-pattern=0
      frame UdsComRx_VIBFromPack1_5: id 0x79E, from VIC, to Info_Node, frame-length=8, can-addressing-mode=EXTENDED, can-frame-rx-behavior=CAN-20, can-frame-tx-behavior=CAN-20  # UDS response message from Pack1_5 routed via VIC
        pdu UdsComRx_VIBFromPack1_5: length=8, unused-bit-pattern=0
      frame UdsComRx_VIBFromPack2_1: id 0x7B0, from VIC, to Info_Node, frame-length=8, can-addressing-mode=EXTENDED, can-frame-rx-behavior=CAN-20, can-frame-tx-behavior=CAN-20  # UDS response message from Pack2_1 routed via VIC
        pdu UdsComRx_VIBFromPack2_1: length=8, unused-bit-pattern=0
      frame UdsComRx_VIBFromPack2_2: id 0x7B6, from VIC, to Info_Node, frame-length=8, can-addressing-mode=EXTENDED, can-frame-rx-behavior=CAN-20, can-frame-tx-behavior=CAN-20  # UDS response message from Pack2_2 routed via VIC
        pdu UdsComRx_VIBFromPack2_2: length=8, unused-bit-pattern=0
      frame UdsComRx_VIBFromPack2_3: id 0x7BC, from VIC, to Info_Node, frame-length=8, can-addressing-mode=EXTENDED, can-frame-rx-behavior=CAN-20, can-frame-tx-behavior=CAN-20  # UDS response message from Pack2_3 routed via VIC
        pdu UdsComRx_VIBFromPack2_3: length=8, unused-bit-pattern=0
      frame UdsComRx_VIBFromPack2_4: id 0x7C2, from VIC, to Info_Node, frame-length=8, can-addressing-mode=EXTENDED, can-frame-rx-behavior=CAN-20, can-frame-tx-behavior=CAN-20  # UDS response message from Pack2_4 routed via VIC
        pdu UdsComRx_VIBFromPack2_4: length=8, unused-bit-pattern=0
      frame UdsComRx_VIBFromPack2_5: id 0x7C8, from VIC, to Info_Node, frame-length=8, can-addressing-mode=EXTENDED, can-frame-rx-behavior=CAN-20, can-frame-tx-behavior=CAN-20  # UDS response message from Pack2_5 routed via VIC
        pdu UdsComRx_VIBFromPack2_5: length=8, unused-bit-pattern=0
      frame XcpComRx_VIB_BMSStdAln: id 0x782, from VIC, to Info_Node, frame-length=8, can-addressing-mode=EXTENDED, can-frame-rx-behavior=CAN-20, can-frame-tx-behavior=CAN-20  # XCP response message from the battery system
        pdu XcpComRx_VIB_BMSStdAln: length=8, unused-bit-pattern=0
      frame XcpComTx_VIBToPack1_1: id 0x688, from Info_Node, to VIC, frame-length=8, can-addressing-mode=EXTENDED, can-frame-rx-behavior=CAN-20, can-frame-tx-behavior=CAN-20  # XCP request message to Pack1_1 routed via VIC
        pdu XcpComTx_VIBToPack1_1: length=8, unused-bit-pattern=0
      frame XcpComTx_VIBToPack1_2: id 0x68E, from Info_Node, to VIC, frame-length=8, can-addressing-mode=EXTENDED, can-frame-rx-behavior=CAN-20, can-frame-tx-behavior=CAN-20  # XCP request message to Pack1_2 routed via VIC
        pdu XcpComTx_VIBToPack1_2: length=8, unused-bit-pattern=0
      frame XcpComTx_VIBToPack1_3: id 0x694, from Info_Node, to VIC, frame-length=8, can-addressing-mode=EXTENDED, can-frame-rx-behavior=CAN-20, can-frame-tx-behavior=CAN-20  # XCP request message to Pack1_3 routed via VIC
        pdu XcpComTx_VIBToPack1_3: length=8, unused-bit-pattern=0
      frame XcpComTx_VIBToPack1_4: id 0x69A, from Info_Node, to VIC, frame-length=8, can-addressing-mode=EXTENDED, can-frame-rx-behavior=CAN-20, can-frame-tx-behavior=CAN-20  # XCP request message to Pack1_4 routed via VIC
        pdu XcpComTx_VIBToPack1_4: length=8, unused-bit-pattern=0
      frame XcpComTx_VIBToPack1_5: id 0x6A0, from Info_Node, to VIC, frame-length=8, can-addressing-mode=EXTENDED, can-frame-rx-behavior=CAN-20, can-frame-tx-behavior=CAN-20  # XCP request message to Pack1_5 routed via VIC
        pdu XcpComTx_VIBToPack1_5: length=8, unused-bit-pattern=0
      frame XcpComTx_VIBToPack2_1: id 0x6B2, from Info_Node, to VIC, frame-length=8, can-addressing-mode=EXTENDED, can-frame-rx-behavior=CAN-20, can-frame-tx-behavior=CAN-20  # XCP request message to Pack2_1 routed via VIC
        pdu XcpComTx_VIBToPack2_1: length=8, unused-bit-pattern=0
      frame XcpComTx_VIBToPack2_2: id 0x6B8, from Info_Node, to VIC, frame-length=8, can-addressing-mode=EXTENDED, can-frame-rx-behavior=CAN-20, can-frame-tx-behavior=CAN-20  # XCP request message to Pack2_2 routed via VIC
        pdu XcpComTx_VIBToPack2_2: length=8, unused-bit-pattern=0
      frame XcpComTx_VIBToPack2_3: id 0x6BE, from Info_Node, to VIC, frame-length=8, can-addressing-mode=EXTENDED, can-frame-rx-behavior=CAN-20, can-frame-tx-behavior=CAN-20  # XCP request message to Pack2_3 routed via VIC
        pdu XcpComTx_VIBToPack2_3: length=8, unused-bit-pattern=0
      frame XcpComTx_VIBToPack2_4: id 0x6C4, from Info_Node, to VIC, frame-length=8, can-addressing-mode=EXTENDED, can-frame-rx-behavior=CAN-20, can-frame-tx-behavior=CAN-20  # XCP request message to Pack2_4 routed via VIC
        pdu XcpComTx_VIBToPack2_4: length=8, unused-bit-pattern=0
      frame XcpComTx_VIBToPack2_5: id 0x6CA, from Info_Node, to VIC, frame-length=8, can-addressing-mode=EXTENDED, can-frame-rx-behavior=CAN-20, can-frame-tx-behavior=CAN-20  # XCP request message to Pack2_5 routed via VIC
        pdu XcpComTx_VIBToPack2_5: length=8, unused-bit-pattern=0
      frame XcpComRx_VIBFromPack1_1: id 0x788, from VIC, to Info_Node, frame-length=8, can-addressing-mode=EXTENDED, can-frame-rx-behavior=CAN-20, can-frame-tx-behavior=CAN-20  # XCP response message from Pack1_1 routed via VIC
        pdu XcpComRx_VIBFromPack1_1: length=8, unused-bit-pattern=0
      frame XcpComRx_VIBFromPack1_2: id 0x78E, from VIC, to Info_Node, frame-length=8, can-addressing-mode=EXTENDED, can-frame-rx-behavior=CAN-20, can-frame-tx-behavior=CAN-20  # XCP response message from Pack1_2 routed via VIC
        pdu XcpComRx_VIBFromPack1_2: length=8, unused-bit-pattern=0
      frame XcpComRx_VIBFromPack1_3: id 0x794, from VIC, to Info_Node, frame-length=8, can-addressing-mode=EXTENDED, can-frame-rx-behavior=CAN-20, can-frame-tx-behavior=CAN-20  # XCP response message from Pack1_3 routed via VIC
        pdu XcpComRx_VIBFromPack1_3: length=8, unused-bit-pattern=0
      frame XcpComRx_VIBFromPack1_4: id 0x79A, from VIC, to Info_Node, frame-length=8, can-addressing-mode=EXTENDED, can-frame-rx-behavior=CAN-20, can-frame-tx-behavior=CAN-20  # XCP response message from Pack1_4 routed via VIC
        pdu XcpComRx_VIBFromPack1_4: length=8, unused-bit-pattern=0
      frame XcpComRx_VIBFromPack1_5: id 0x7A0, from VIC, to Info_Node, frame-length=8, can-addressing-mode=EXTENDED, can-frame-rx-behavior=CAN-20, can-frame-tx-behavior=CAN-20  # XCP response message from Pack1_5 routed via VIC
        pdu XcpComRx_VIBFromPack1_5: length=8, unused-bit-pattern=0
      frame XcpComRx_VIBFromPack2_1: id 0x7B2, from VIC, to Info_Node, frame-length=8, can-addressing-mode=EXTENDED, can-frame-rx-behavior=CAN-20, can-frame-tx-behavior=CAN-20  # XCP response message from Pack2_1 routed via VIC
        pdu XcpComRx_VIBFromPack2_1: length=8, unused-bit-pattern=0
      frame XcpComRx_VIBFromPack2_2: id 0x7B8, from VIC, to Info_Node, frame-length=8, can-addressing-mode=EXTENDED, can-frame-rx-behavior=CAN-20, can-frame-tx-behavior=CAN-20  # XCP response message from Pack2_2 routed via VIC
        pdu XcpComRx_VIBFromPack2_2: length=8, unused-bit-pattern=0
      frame XcpComRx_VIBFromPack2_3: id 0x7BE, from VIC, to Info_Node, frame-length=8, can-addressing-mode=EXTENDED, can-frame-rx-behavior=CAN-20, can-frame-tx-behavior=CAN-20  # XCP response message from Pack2_3 routed via VIC
        pdu XcpComRx_VIBFromPack2_3: length=8, unused-bit-pattern=0
      frame XcpComRx_VIBFromPack2_4: id 0x7C4, from VIC, to Info_Node, frame-length=8, can-addressing-mode=EXTENDED, can-frame-rx-behavior=CAN-20, can-frame-tx-behavior=CAN-20  # XCP response message from Pack2_4 routed via VIC
        pdu XcpComRx_VIBFromPack2_4: length=8, unused-bit-pattern=0
      frame XcpComRx_VIBFromPack2_5: id 0x7CA, from VIC, to Info_Node, frame-length=8, can-addressing-mode=EXTENDED, can-frame-rx-behavior=CAN-20, can-frame-tx-behavior=CAN-20  # XCP response message from Pack2_5 routed via VIC
        pdu XcpComRx_VIBFromPack2_5: length=8, unused-bit-pattern=0
package /Vehicle_CAN_Bus/DataTypes
  base type Alvctr_Coding: category=FIXED_LENGTH, base-type-size=8, base-type-encoding=NONE, mem-alignment=0, native-declaration=unsigned char
  base type AvlE_Coding: category=FIXED_LENGTH, base-type-size=16, base-type-encoding=NONE, mem-alignment=0, native-declaration=unsigned short
  unit AvlE_Unit: display-name=kWh
  base type BatSt_Coding: category=FIXED_LENGTH, base-type-size=8, base-type-encoding=NONE, mem-alignment=0, native-declaration=unsigned char
  base type CellTPermsnToCls_Coding: category=FIXED_LENGTH, base-type-size=8, base-type-encoding=NONE, mem-alignment=0, native-declaration=unsigned char
  base type CellUPermsnToCls_Coding: category=FIXED_LENGTH, base-type-size=8, base-type-encoding=NONE, mem-alignment=0, native-declaration=unsigned char
  base type Cks_Coding: category=FIXED_LENGTH, base-type-size=8, base-type-encoding=NONE, mem-alignment=0, native-declaration=unsigned char
  base type CmptbltyIdx_Coding: category=FIXED_LENGTH, base-type-size=16, base-type-encoding=NONE, mem-alignment=0, native-declaration=unsigned char
  base type CoolgHeatgCfmd_Coding: category=FIXED_LENGTH, base-type-size=16, base-type-encoding=NONE, mem-alignment=0, native-declaration=unsigned char
  unit CoolgHeatgCfmd_Unit
  base type CoolgHeatgReq_Coding: category=FIXED_LENGTH, base-type-size=8, base-type-encoding=NONE, mem-alignment=0, native-declaration=unsigned char
  base type CptTPermsnToCls_Coding: category=FIXED_LENGTH, base-type-size=8, base-type-encoding=NONE, mem-alignment=0, native-declaration=unsigned char
  base type CrashDetnNeg_Coding: category=FIXED_LENGTH, base-type-size=8, base-type-encoding=NONE, mem-alignment=0, native-declaration=unsigned char
  base type CrashPermsnToCls_Coding: category=FIXED_LENGTH, base-type-size=8, base-type-encoding=NONE, mem-alignment=0, native-declaration=unsigned char
  base type CtctrStuckPermsnToCls_Coding: category=FIXED_LENGTH, base-type-size=8, base-type-encoding=NONE, mem-alignment=0, native-declaration=unsigned char
  base type DIDNibble_Coding: category=FIXED_LENGTH, base-type-size=8, base-type-encoding=NONE, mem-alignment=0, native-declaration=unsigned char
  base type Day_Coding: category=FIXED_LENGTH, base-type-size=8, base-type-encoding=NONE, mem-alignment=0, native-declaration=unsigned char
  unit Day_Unit: display-name=days
  base type DcChCtctrPermsnToCls_Coding: category=FIXED_LENGTH, base-type-size=8, base-type-encoding=NONE, mem-alignment=0, native-declaration=unsigned char
  base type DcnctPndCtr_Coding: category=FIXED_LENGTH, base-type-size=8, base-type-encoding=NONE, mem-alignment=0, native-declaration=unsigned char
  unit DcnctPndCtr_Unit: display-name=ms
  base type DcnctPndFlag_Coding: category=FIXED_LENGTH, base-type-size=8, base-type-encoding=NONE, mem-alignment=0, native-declaration=unsigned char
  base type EcuCalVersBuild_Coding: category=FIXED_LENGTH, base-type-size=8, base-type-encoding=NONE, mem-alignment=0, native-declaration=unsigned char
  base type EcuCalVersCusVrnt_Coding: category=FIXED_LENGTH, base-type-size=8, base-type-encoding=NONE, mem-alignment=0, native-declaration=unsigned char
  base type EcuCalVersMid_Coding: category=FIXED_LENGTH, base-type-size=16, base-type-encoding=NONE, mem-alignment=0, native-declaration=unsigned char
  base type EcuCalVersMjr_Coding: category=FIXED_LENGTH, base-type-size=16, base-type-encoding=NONE, mem-alignment=0, native-declaration=unsigned char
  base type EcuCalVersMnr_Coding: category=FIXED_LENGTH, base-type-size=16, base-type-encoding=NONE, mem-alignment=0, native-declaration=unsigned char
  base type EcuCalVersSwEcuTyp_Coding: category=FIXED_LENGTH, base-type-size=16, base-type-encoding=NONE, mem-alignment=0, native-declaration=unsigned char
  base type EcuCalVersSwVrnt_Coding: category=FIXED_LENGTH, base-type-size=16, base-type-encoding=NONE, mem-alignment=0, native-declaration=unsigned char
  base type EcuHwNr_Coding: category=FIXED_LENGTH, base-type-size=16, base-type-encoding=NONE, mem-alignment=0, native-declaration=unsigned short
  base type EcuHwVers_Coding: category=FIXED_LENGTH, base-type-size=16, base-type-encoding=NONE, mem-alignment=0, native-declaration=unsigned short
  base type EcuSbTypBms_Coding: category=FIXED_LENGTH, base-type-size=8, base-type-encoding=NONE, mem-alignment=0, native-declaration=unsigned char
  base type EcuSbTypVic_Coding: category=FIXED_LENGTH, base-type-size=8, base-type-encoding=NONE, mem-alignment=0, native-declaration=unsigned char
  base type EcuSt_Coding: category=FIXED_LENGTH, base-type-size=8, base-type-encoding=NONE, mem-alignment=0, native-declaration=unsigned char
  base type EcuSwNrCusVrnt_Coding: category=FIXED_LENGTH, base-type-size=16, base-type-encoding=NONE, mem-alignment=0, native-declaration=unsigned char
  base type EcuSwNrSwEcuTyp_Coding: category=FIXED_LENGTH, base-type-size=16, base-type-encoding=NONE, mem-alignment=0, native-declaration=unsigned char
  base type EcuSwNrSwVrnt_Coding: category=FIXED_LENGTH, base-type-size=16, base-type-encoding=NONE, mem-alignment=0, native-declaration=unsigned char
  base type EcuSwVersNrBuild_Coding: category=FIXED_LENGTH, base-type-size=16, base-type-encoding=NONE, mem-alignment=0, native-declaration=unsigned char
  base type EcuSwVersNrMid_Coding: category=FIXED_LENGTH, base-type-size=16, base-type-encoding=NONE, mem-alignment=0, native-declaration=unsigned char
  base type EcuSwVersNrMjr_Coding: category=FIXED_LENGTH, base-type-size=16, base-type-encoding=NONE, mem-alignment=0, native-declaration=unsigned char
  base type EcuSwVersNrMnr_Coding: category=FIXED_LENGTH, base-type-size=16, base-type-encoding=NONE, mem-alignment=0, native-declaration=unsigned char
  base type EcuTyp_Coding: category=FIXED_LENGTH, base-type-size=8, base-type-encoding=NONE, mem-alignment=0, native-declaration=unsigned char
  base type EnaCoolgHeatgBatFlag_Coding: category=FIXED_LENGTH, base-type-size=8, base-type-encoding=NONE, mem-alignment=0, native-declaration=unsigned char
  base type ErrLvl_Coding: category=FIXED_LENGTH, base-type-size=8, base-type-encoding=NONE, mem-alignment=0, native-declaration=unsigned char
  base type Generic_Coding: category=FIXED_LENGTH, base-type-size=64, base-type-encoding=NONE, mem-alignment=0, native-declaration=unsigned long
  compu method Generic_CompuMethod: identical
  range Generic_PHYSICAL_VALID: phys 0..1.84467440737096e+19
  base type Hour_Coding: category=FIXED_LENGTH, base-type-size=8, base-type-encoding=NONE, mem-alignment=0, native-declaration=unsigned char
  unit Hour_Unit: display-name=h
  base type HvReq_Coding: category=FIXED_LENGTH, base-type-size=8, base-type-encoding=NONE, mem-alignment=0, native-declaration=unsigned char
  base type HvilPermsnToCls_Coding: category=FIXED_LENGTH, base-type-size=8, base-type-encoding=NONE, mem-alignment=0, native-declaration=unsigned char
  base type IChLimLong_Coding: category=FIXED_LENGTH, base-type-size=16, base-type-encoding=NONE, mem-alignment=0, native-declaration=unsigned short
  unit IChLimLong_Unit: display-name=A
  base type IChLimSho_Coding: category=FIXED_LENGTH, base-type-size=16, base-type-encoding=NONE, mem-alignment=0, native-declaration=unsigned short
  unit IChLimSho_Unit: display-name=A
  base type IDchaLimLong_Coding: category=FIXED_LENGTH, base-type-size=16, base-type-encoding=NONE, mem-alignment=0, native-declaration=unsigned short
  unit IDchaLimLong_Unit: display-name=A
  base type IDchaLimSho_Coding: category=FIXED_LENGTH, base-type-size=16, base-type-encoding=NONE, mem-alignment=0, native-declaration=unsigned short
  unit IDchaLimSho_Unit: display-name=A
  base type IPermsnToCls_Coding: category=FIXED_LENGTH, base-type-size=8, base-type-encoding=NONE, mem-alignment=0, native-declaration=unsigned char
  base type I_Coding: category=FIXED_LENGTH, base-type-size=16, base-type-encoding=2C, mem-alignment=0, native-declaration=short
  unit I_Unit: display-name=A
  base type IslnMeastDisaCmd_Coding: category=FIXED_LENGTH, base-type-size=8, base-type-encoding=NONE, mem-alignment=0, native-declaration=unsigned char
  base type IslnPermsnToCls_Coding: category=FIXED_LENGTH, base-type-size=8, base-type-encoding=NONE, mem-alignment=0, native-declaration=unsigned char
  base type LockMemPermsnToCls_Coding: category=FIXED_LENGTH, base-type-size=8, base-type-encoding=NONE, mem-alignment=0, native-declaration=unsigned char
  base type Minu_Coding: category=FIXED_LENGTH, base-type-size=8, base-type-encoding=NONE, mem-alignment=0, native-declaration=unsigned char
  unit Minu_Unit: display-name=min
  base type Month_Coding: category=FIXED_LENGTH, base-type-size=8, base-type-encoding=NONE, mem-alignment=0, native-declaration=unsigned char
  unit Month_Unit: display-name=months
  unit NoUnit
  base type P_Coding: category=FIXED_LENGTH, base-type-size=16, base-type-encoding=2C, mem-alignment=0, native-declaration=short
  unit P_Unit: display-name=kW
  base type PackNameThermReq1_Coding: category=FIXED_LENGTH, base-type-size=8, base-type-encoding=NONE, mem-alignment=0, native-declaration=unsigned char
  base type PackName_Coding: category=FIXED_LENGTH, base-type-size=8, base-type-encoding=NONE, mem-alignment=0, native-declaration=unsigned char
  base type RIsln_Coding: category=FIXED_LENGTH, base-type-size=16, base-type-encoding=NONE, mem-alignment=0, native-declaration=unsigned long
  unit RIsln_Unit: display-name=kOhm
  base type RPrecOvtempFlag_Coding: category=FIXED_LENGTH, base-type-size=8, base-type-encoding=NONE, mem-alignment=0, native-declaration=unsigned char
  base type Sec_Coding: category=FIXED_LENGTH, base-type-size=8, base-type-encoding=NONE, mem-alignment=0, native-declaration=unsigned char
  unit Sec_Unit: display-name=s
  base type SftyOk_Coding: category=FIXED_LENGTH, base-type-size=8, base-type-encoding=NONE, mem-alignment=0, native-declaration=unsigned char
  base type SftySt_Coding: category=FIXED_LENGTH, base-type-size=8, base-type-encoding=NONE, mem-alignment=0, native-declaration=unsigned char
  base type Soc_Coding: category=FIXED_LENGTH, base-type-size=16, base-type-encoding=NONE, mem-alignment=0, native-declaration=unsigned short
  unit Soc_Unit: display-name=%
  base type Soh_Coding: category=FIXED_LENGTH, base-type-size=16, base-type-encoding=NONE, mem-alignment=0, native-declaration=unsigned short
  unit Soh_Unit: display-name=%
  base type StCtctrNeg_Coding: category=FIXED_LENGTH, base-type-size=8, base-type-encoding=NONE, mem-alignment=0, native-declaration=unsigned char
  base type StCtctrPos_Coding: category=FIXED_LENGTH, base-type-size=8, base-type-encoding=NONE, mem-alignment=0, native-declaration=unsigned char
  base type StCtctrPrec_Coding: category=FIXED_LENGTH, base-type-size=8, base-type-encoding=NONE, mem-alignment=0, native-declaration=unsigned char
  base type StsIslnMeast_Coding: category=FIXED_LENGTH, base-type-size=8, base-type-encoding=NONE, mem-alignment=0, native-declaration=unsigned char
  base type TAct_Coding: category=FIXED_LENGTH, base-type-size=16, base-type-encoding=2C, mem-alignment=0, native-declaration=short
  unit TAct_Unit: display-name=°C
  base type TAmb_Coding: category=FIXED_LENGTH, base-type-size=16, base-type-encoding=2C, mem-alignment=0, native-declaration=short
  unit TAmb_Unit: display-name=°C
  base type TCellMax_Coding: category=FIXED_LENGTH, base-type-size=16, base-type-encoding=2C, mem-alignment=0, native-declaration=short
  unit TCellMax_Unit: display-name=°C
  base type TCellMin_Coding: category=FIXED_LENGTH, base-type-size=16, base-type-encoding=2C, mem-alignment=0, native-declaration=short
  unit TCellMin_Unit: display-name=°C
  base type TSetPoint_Coding: category=FIXED_LENGTH, base-type-size=16, base-type-encoding=2C, mem-alignment=0, native-declaration=short
  unit TSetPoint_Unit: display-name=°C
  base type ThermEveStsCellT_Coding: category=FIXED_LENGTH, base-type-size=8, base-type-encoding=NONE, mem-alignment=0, native-declaration=unsigned char
  base type ThermRunAwPermsnToCls_Coding: category=FIXED_LENGTH, base-type-size=8, base-type-encoding=NONE, mem-alignment=0, native-declaration=unsigned char
  base type ThermSysStrtReq1_Coding: category=FIXED_LENGTH, base-type-size=8, base-type-encoding=NONE, mem-alignment=0, native-declaration=unsigned char
  base type ThermSysStrtReq2_Coding: category=FIXED_LENGTH, base-type-size=8, base-type-encoding=NONE, mem-alignment=0, native-declaration=unsigned char
  base type UBat_Coding: category=FIXED_LENGTH, base-type-size=16, base-type-encoding=NONE, mem-alignment=0, native-declaration=unsigned short
  unit UBat_Unit: display-name=V
  base type UCellMax_Coding: category=FIXED_LENGTH, base-type-size=16, base-type-encoding=NONE, mem-alignment=0, native-declaration=unsigned short
  unit UCellMax_Unit: display-name=V
  base type UCellMin_Coding: category=FIXED_LENGTH, base-type-size=16, base-type-encoding=NONE, mem-alignment=0, native-declaration=unsigned short
  unit UCellMin_Unit: display-name=V
  base type UChLimLong_Coding: category=FIXED_LENGTH, base-type-size=16, base-type-encoding=NONE, mem-alignment=0, native-declaration=unsigned short
  unit UChLimLong_Unit: display-name=V
  base type UChLimSho_Coding: category=FIXED_LENGTH, base-type-size=16, base-type-encoding=NONE, mem-alignment=0, native-declaration=unsigned short
  unit UChLimSho_Unit: display-name=V
  base type UDcLnk_Coding: category=FIXED_LENGTH, base-type-size=16, base-type-encoding=NONE, mem-alignment=0, native-declaration=unsigned short
  unit UDcLnk_Unit: display-name=V
  base type UDchaLimLong_Coding: category=FIXED_LENGTH, base-type-size=16, base-type-encoding=NONE, mem-alignment=0, native-declaration=unsigned short
  unit UDchaLimLong_Unit: display-name=V
  base type UDchaLimSho_Coding: category=FIXED_LENGTH, base-type-size=16, base-type-encoding=NONE, mem-alignment=0, native-declaration=unsigned short
  unit UDchaLimSho_Unit: display-name=V
  base type UExpdCh_Coding: category=FIXED_LENGTH, base-type-size=16, base-type-encoding=NONE, mem-alignment=0, native-declaration=unsigned short
  unit UExpdCh_Unit: display-name=V
  base type UExpdDrvg_Coding: category=FIXED_LENGTH, base-type-size=16, base-type-encoding=NONE, mem-alignment=0, native-declaration=unsigned short
  unit UExpdDrvg_Unit: display-name=V
  base type ULnkMps_Coding: category=FIXED_LENGTH, base-type-size=16, base-type-encoding=2C, mem-alignment=0, native-declaration=short
  unit ULnkMps_Unit: display-name=V
  base type ULnkSng_Coding: category=FIXED_LENGTH, base-type-size=16, base-type-encoding=2C, mem-alignment=0, native-declaration=short
  unit ULnkSng_Unit: display-name=V
  base type VehSpd_Coding: category=FIXED_LENGTH, base-type-size=16, base-type-encoding=2C, mem-alignment=0, native-declaration=short
  unit VehSpd_Unit: display-name=km/h
  base type Year_Coding: category=FIXED_LENGTH, base-type-size=16, base-type-encoding=NONE, mem-alignment=0, native-declaration=unsigned short
  unit Year_Unit: display-name=years
package /Vehicle_CAN_Bus/ECUs
  ecu instance Thermal_Management_System_ECU: diagnostic-address=0, sleep-mode-supported=true, wake-up-over-bus-supported=true
    can communication controller Thermal_Management_System_ECU_CANController
    can communication connector Thermal_Management_System_ECU_CANConnector: comm-controller=Thermal_Management_System_ECU_CANController
  ecu instance Vehicle_Control_Unit: diagnostic-address=1628701155, sleep-mode-supported=true, wake-up-over-bus-supported=true
    can communication controller Vehicle_Control_Unit_CANController
    can communication controller Vehicle_Control_Unit_CANController_J1939
    can communication connector Vehicle_Control_Unit_CANConnector: comm-controller=Vehicle_Control_Unit_CANController
    can communication connector Vehicle_Control_Unit_CANConnector_J1939: comm-controller=Vehicle_Control_Unit_CANController_J1939
package /Vehicle_CAN_Bus/ISignalGroups
  8 x i signal group, all with com-based-signal-group-transformations=BaseTrans_Profile_1C:
    BatInfo: i-signal=[ThermEveStsCellT, P, StsIslnMeast, RIsln, RPrecOvtempFlag, DcnctPndFlag, DcnctPndCtr, BatInfo_Cks, BatInfo_Alvctr, BatInfo_DIDNibble], system-signal-group=BatInfo, end-to-end-transformation-i-signal-props{transformer=E2E_Profile_1C, data-ids=1039, data-length=64}  # A group of all SystemSignals in BatInfo along with the E2E signals
    BatPermsnToCls: i-signal=[IPermsnToCls, IslnPermsnToCls, CtctrStuckPermsnToCls, DcChCtctrPermsnToCls, ThermRunAwPermsnToCls, CrashPermsnToCls, LockMemPermsnToCls, CptTPermsnToCls, CellUPermsnToCls, CellTPermsnToCls, BatPermsnToCls_Cks, BatPermsnToCls_Alvctr, BatPermsnToCls_DIDNibble], system-signal-group=BatPermsnToCls, end-to-end-transformation-i-signal-props{transformer=E2E_Profile_1C, data-ids=271, data-length=56}  # A group of all SystemSignals in BatPermsnToCls along with the E2E signals
    BatSts: i-signal=[BatSt, EcuSt, SftySt, ErrLvl, HvilPermsnToCls, I, StCtctrPos, StCtctrNeg, StCtctrPrec, BatSts_Cks, BatSts_Alvctr, BatSts_DIDNibble], system-signal-group=BatSts, end-to-end-transformation-i-signal-props{transformer=E2E_Profile_1C, data-ids=527, data-length=56}  # A group of all SystemSignals in BatSts along with the E2E signals
    BatUMps: i-signal=[BatUMps_Cks, BatUMps_Alvctr, BatUMps_DIDNibble, ULnkMps, UExpdCh, UExpdDrvg, UDcLnk], system-signal-group=BatUMps, end-to-end-transformation-i-signal-props{transformer=E2E_Profile_1C, data-ids=783, data-length=64}  # A group of all SystemSignals in BatUMps along with the E2E signals
    BatUSng: i-signal=[ULnkSng, UBat, BatUSng_Cks, BatUSng_Alvctr, BatUSng_DIDNibble], system-signal-group=BatUSng, end-to-end-transformation-i-signal-props{transformer=E2E_Profile_1C, data-ids=783, data-length=40}  # A group of all SystemSignals in BatUSng along with the E2E signals
    CtlCmd: i-signal=[IslnMeastDisaCmd, HvReq, CtlCmd_Cks, CtlCmd_Alvctr, CtlCmd_DIDNibble], system-signal-group=CtlCmd, end-to-end-transformation-i-signal-props{transformer=E2E_Profile_1C, data-ids=1551, data-length=32}  # A group of all SystemSignals in CtlCmd along with the E2E signals
    SftyInfo: i-signal=[SftyOk, CrashDetnNeg, SftyInfo_Cks, SftyInfo_Alvctr, SftyInfo_DIDNibble], system-signal-group=SftyInfo, end-to-end-transformation-i-signal-props{transformer=E2E_Profile_1C, data-ids=2239, data-length=24}  # A group of all SystemSignals in SftyInfo along with the E2E signals
    VehInfo: i-signal=[VehSpd, TAmb, VehInfo_Cks, VehInfo_Alvctr, VehInfo_DIDNibble], system-signal-group=VehInfo, end-to-end-transformation-i-signal-props{transformer=E2E_Profile_1C, data-ids=1456, data-length=48}  # A group of all SystemSignals in VehInfo along with the E2E signals
